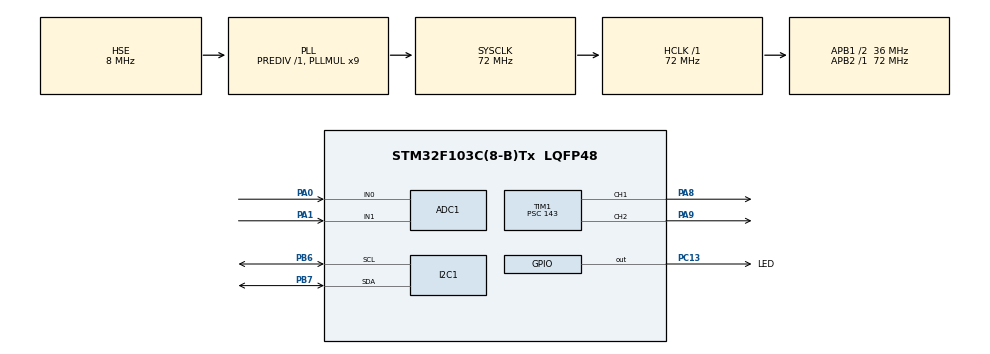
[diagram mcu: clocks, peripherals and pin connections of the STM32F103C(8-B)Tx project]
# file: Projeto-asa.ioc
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ADC1.Channel-0\#ChannelRegularConversion=ADC_CHANNEL_0
ADC1.Channel-1\#ChannelRegularConversion=ADC_CHANNEL_1
ADC1.ContinuousConvMode=DISABLE
ADC1.ExternalTrigConv=ADC_EXTERNALTRIGCONV_T3_TRGO
ADC1.NbrOfConversion=2
ADC1.NbrOfConversionFlag=1
ADC1.Rank-0\#ChannelRegularConversion=1
ADC1.Rank-1\#ChannelRegularConversion=2
ADC1.SamplingTime-0\#ChannelRegularConversion=ADC_SAMPLETIME_28CYCLES_5
ADC1.SamplingTime-1\#ChannelRegularConversion=ADC_SAMPLETIME_28CYCLES_5
ADC1.master=1
Dma.ADC1.0.Direction=DMA_PERIPH_TO_MEMORY
Dma.ADC1.0.Instance=DMA1_Channel1
Dma.ADC1.0.MemDataAlignment=DMA_MDATAALIGN_WORD
Dma.ADC1.0.MemInc=DMA_MINC_ENABLE
Dma.ADC1.0.Mode=DMA_CIRCULAR
Dma.ADC1.0.PeriphDataAlignment=DMA_PDATAALIGN_WORD
Dma.ADC1.0.PeriphInc=DMA_PINC_DISABLE
Dma.ADC1.0.Priority=DMA_PRIORITY_HIGH
Dma.Request0=ADC1
I2C1.I2C_Mode=I2C_Fast
Mcu.Family=STM32F1
Mcu.Name=STM32F103C(8-B)Tx
Mcu.Package=LQFP48
NVIC.ADC1_2_IRQn=true\:0\:0\:false\:false\:true\:true\:true
NVIC.DMA1_Channel1_IRQn=true\:0\:0\:false\:false\:true\:false\:true
NVIC.I2C1_ER_IRQn=true\:0\:0\:false\:false\:true\:true\:true
NVIC.I2C1_EV_IRQn=true\:0\:0\:false\:false\:true\:true\:true
NVIC.PriorityGroup=NVIC_PRIORITYGROUP_4
NVIC.TIM1_BRK_IRQn=true\:0\:0\:false\:false\:true\:true\:true
NVIC.TIM1_CC_IRQn=true\:0\:0\:false\:false\:true\:true\:true
NVIC.TIM1_TRG_COM_IRQn=true\:0\:0\:false\:false\:true\:true\:true
NVIC.TIM1_UP_IRQn=true\:0\:0\:false\:false\:true\:true\:true
PA0-WKUP.Signal=ADCx_IN0
PA1.Signal=ADCx_IN1
PA13.Mode=Serial_Wire
PA13.Signal=SYS_JTMS-SWDIO
PA14.Mode=Serial_Wire
PA14.Signal=SYS_JTCK-SWCLK
PA8.Signal=S_TIM1_CH1
PA9.Signal=S_TIM1_CH2
PB6.Mode=I2C
PB6.Signal=I2C1_SCL
PB7.Mode=I2C
PB7.Signal=I2C1_SDA
PC13-TAMPER-RTC.GPIO_Label=LED
PC13-TAMPER-RTC.Signal=GPIO_Output
PD0-OSC_IN.Mode=HSE-External-Clock-Source
PD0-OSC_IN.Signal=RCC_OSC_IN
PD1-OSC_OUT.Mode=HSE-External-Clock-Source
PD1-OSC_OUT.Signal=RCC_OSC_OUT
ProjectManager.HeapSize=0x200
ProjectManager.StackSize=0x400
ProjectManager.TargetToolchain=TrueSTUDIO
RCC.ADCPresc=RCC_ADCPCLK2_DIV8
RCC.AHBFreq_Value=72000000
RCC.APB1CLKDivider=RCC_HCLK_DIV2
RCC.APB1Freq_Value=36000000
RCC.APB1TimFreq_Value=72000000
RCC.APB2Freq_Value=72000000
RCC.APB2TimFreq_Value=72000000
RCC.HCLKFreq_Value=72000000
RCC.PLLMUL=RCC_PLL_MUL9
RCC.PLLSourceVirtual=RCC_PLLSOURCE_HSE
RCC.SYSCLKFreq_VALUE=72000000
RCC.SYSCLKSource=RCC_SYSCLKSOURCE_PLLCLK
RCC.USBFreq_Value=72000000
SH.ADCx_IN0.0=ADC1_IN0,IN0
SH.ADCx_IN1.0=ADC1_IN1,IN1
SH.S_TIM1_CH1.0=TIM1_CH1,PWM Generation1 CH1
SH.S_TIM1_CH2.0=TIM1_CH2,PWM Generation2 CH2
TIM1.Channel-PWM\ Generation1\ CH1=TIM_CHANNEL_1
TIM1.Channel-PWM\ Generation2\ CH2=TIM_CHANNEL_2
TIM1.Period=10000
TIM1.Prescaler=143
TIM1.Pulse-PWM\ Generation1\ CH1=5000
TIM1.Pulse-PWM\ Generation2\ CH2=4999
TIM3.Period=1439
TIM3.Prescaler=999
TIM3.TIM_MasterOutputTrigger=TIM_TRGO_UPDATE
VP_TIM3_VS_ClockSourceINT.Mode=Internal
board=custom

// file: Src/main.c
/* USER CODE BEGIN Header */
/**
  ******************************************************************************
  * @file           : main.c
  * @brief          : Main program body
  ******************************************************************************
  * @attention
  *
  * <h2><center>&copy; Copyright (c) 2019 STMicroelectronics.
  * All rights reserved.</center></h2>
  *
  * This software component is licensed by ST under BSD 3-Clause license,
  * the "License"; You may not use this file except in compliance with the
  * License. You may obtain a copy of the License at:
  *                        opensource.org/licenses/BSD-3-Clause
  *
  ******************************************************************************
  */
/* USER CODE END Header */

#include "main.h"

ADC_HandleTypeDef hadc1;
DMA_HandleTypeDef hdma_adc1;

I2C_HandleTypeDef hi2c1;

TIM_HandleTypeDef htim1;
TIM_HandleTypeDef htim3;

/* USER CODE BEGIN PV */
uint8_t rawMpu[6];
uint32_t rawAdc[2];
uint32_t servoPosition;
/* USER CODE END PV */

void SystemClock_Config(void);
static void MX_GPIO_Init(void);
static void MX_DMA_Init(void);
static void MX_ADC1_Init(void);
static void MX_I2C1_Init(void);
static void MX_TIM1_Init(void);
static void MX_TIM3_Init(void);

int main(void)
{
  /* USER CODE BEGIN 1 */
    uint8_t mpuConfig;
  /* USER CODE END 1 */

  /* MCU Configuration--------------------------------------------------------*/

  /* Reset of all peripherals, Initializes the Flash interface and the Systick. */
  HAL_Init();

  /* Configure the system clock */
  SystemClock_Config();

  /* Initialize all configured peripherals */
  MX_GPIO_Init();
  MX_DMA_Init();
  MX_ADC1_Init();
  MX_I2C1_Init();
  MX_TIM1_Init();
  MX_TIM3_Init();
  /* USER CODE BEGIN 2 */
 // mpuConfig = 0b00000000;
 // HAL_I2C_Mem_Write(&hi2c1, 0x68, 0x6B, I2C_MEMADD_SIZE_8BIT, &mpuConfig, 1, 100); //

  HAL_TIM_PWM_Start(&htim1, TIM_CHANNEL_1);
  HAL_TIM_PWM_Start(&htim1, TIM_CHANNEL_2);
  HAL_TIM_Base_Start_IT(&htim3);
  HAL_ADCEx_Calibration_Start(&hadc1);
  HAL_ADC_Start_DMA(&hadc1, (uint32_t*)rawAdc, 2);

  /* USER CODE END 2 */

  /* Infinite loop */
  while (1)
  {

    /* USER CODE BEGIN 3 */
	  HAL_Delay(100);
  }
  /* USER CODE END 3 */
}

void SystemClock_Config(void)
{
  RCC_OscInitTypeDef RCC_OscInitStruct = {0};
  RCC_ClkInitTypeDef RCC_ClkInitStruct = {0};
  RCC_PeriphCLKInitTypeDef PeriphClkInit = {0};

  /** Initializes the CPU, AHB and APB busses clocks
  */
  RCC_OscInitStruct.OscillatorType = RCC_OSCILLATORTYPE_HSE;
  RCC_OscInitStruct.HSEState = RCC_HSE_BYPASS;
  RCC_OscInitStruct.HSEPredivValue = RCC_HSE_PREDIV_DIV1;
  RCC_OscInitStruct.HSIState = RCC_HSI_ON;
  RCC_OscInitStruct.PLL.PLLState = RCC_PLL_ON;
  RCC_OscInitStruct.PLL.PLLSource = RCC_PLLSOURCE_HSE;
  RCC_OscInitStruct.PLL.PLLMUL = RCC_PLL_MUL9;
  if (HAL_RCC_OscConfig(&RCC_OscInitStruct) != HAL_OK)
  {
    Error_Handler();
  }
  /** Initializes the CPU, AHB and APB busses clocks
  */
  RCC_ClkInitStruct.ClockType = RCC_CLOCKTYPE_HCLK|RCC_CLOCKTYPE_SYSCLK
                              |RCC_CLOCKTYPE_PCLK1|RCC_CLOCKTYPE_PCLK2;
  RCC_ClkInitStruct.SYSCLKSource = RCC_SYSCLKSOURCE_PLLCLK;
  RCC_ClkInitStruct.AHBCLKDivider = RCC_SYSCLK_DIV1;
  RCC_ClkInitStruct.APB1CLKDivider = RCC_HCLK_DIV2;
  RCC_ClkInitStruct.APB2CLKDivider = RCC_HCLK_DIV1;

  if (HAL_RCC_ClockConfig(&RCC_ClkInitStruct, FLASH_LATENCY_2) != HAL_OK)
  {
    Error_Handler();
  }
  PeriphClkInit.PeriphClockSelection = RCC_PERIPHCLK_ADC;
  PeriphClkInit.AdcClockSelection = RCC_ADCPCLK2_DIV8;
  if (HAL_RCCEx_PeriphCLKConfig(&PeriphClkInit) != HAL_OK)
  {
    Error_Handler();
  }
}

static void MX_ADC1_Init(void)
{

  ADC_ChannelConfTypeDef sConfig = {0};

  /** Common config
  */
  hadc1.Instance = ADC1;
  hadc1.Init.ScanConvMode = ADC_SCAN_ENABLE;
  hadc1.Init.ContinuousConvMode = DISABLE;
  hadc1.Init.DiscontinuousConvMode = DISABLE;
  hadc1.Init.ExternalTrigConv = ADC_EXTERNALTRIGCONV_T3_TRGO;
  hadc1.Init.DataAlign = ADC_DATAALIGN_RIGHT;
  hadc1.Init.NbrOfConversion = 2;
  if (HAL_ADC_Init(&hadc1) != HAL_OK)
  {
    Error_Handler();
  }
  /** Configure Regular Channel
  */
  sConfig.Channel = ADC_CHANNEL_0;
  sConfig.Rank = ADC_REGULAR_RANK_1;
  sConfig.SamplingTime = ADC_SAMPLETIME_28CYCLES_5;
  if (HAL_ADC_ConfigChannel(&hadc1, &sConfig) != HAL_OK)
  {
    Error_Handler();
  }
  /** Configure Regular Channel
  */
  sConfig.Channel = ADC_CHANNEL_1;
  sConfig.Rank = ADC_REGULAR_RANK_2;
  if (HAL_ADC_ConfigChannel(&hadc1, &sConfig) != HAL_OK)
  {
    Error_Handler();
  }

}

static void MX_I2C1_Init(void)
{

  hi2c1.Instance = I2C1;
  hi2c1.Init.ClockSpeed = 400000;
  hi2c1.Init.DutyCycle = I2C_DUTYCYCLE_2;
  hi2c1.Init.OwnAddress1 = 0;
  hi2c1.Init.AddressingMode = I2C_ADDRESSINGMODE_7BIT;
  hi2c1.Init.DualAddressMode = I2C_DUALADDRESS_DISABLE;
  hi2c1.Init.OwnAddress2 = 0;
  hi2c1.Init.GeneralCallMode = I2C_GENERALCALL_DISABLE;
  hi2c1.Init.NoStretchMode = I2C_NOSTRETCH_DISABLE;
  if (HAL_I2C_Init(&hi2c1) != HAL_OK)
  {
    Error_Handler();
  }

}

static void MX_TIM1_Init(void)
{

  TIM_MasterConfigTypeDef sMasterConfig = {0};
  TIM_OC_InitTypeDef sConfigOC = {0};
  TIM_BreakDeadTimeConfigTypeDef sBreakDeadTimeConfig = {0};

  htim1.Instance = TIM1;
  htim1.Init.Prescaler = 143;
  htim1.Init.CounterMode = TIM_COUNTERMODE_UP;
  htim1.Init.Period = 10000;
  htim1.Init.ClockDivision = TIM_CLOCKDIVISION_DIV1;
  htim1.Init.RepetitionCounter = 0;
  htim1.Init.AutoReloadPreload = TIM_AUTORELOAD_PRELOAD_DISABLE;
  if (HAL_TIM_PWM_Init(&htim1) != HAL_OK)
  {
    Error_Handler();
  }
  sMasterConfig.MasterOutputTrigger = TIM_TRGO_RESET;
  sMasterConfig.MasterSlaveMode = TIM_MASTERSLAVEMODE_DISABLE;
  if (HAL_TIMEx_MasterConfigSynchronization(&htim1, &sMasterConfig) != HAL_OK)
  {
    Error_Handler();
  }
  sConfigOC.OCMode = TIM_OCMODE_PWM1;
  sConfigOC.Pulse = 5000;
  sConfigOC.OCPolarity = TIM_OCPOLARITY_HIGH;
  sConfigOC.OCNPolarity = TIM_OCNPOLARITY_HIGH;
  sConfigOC.OCFastMode = TIM_OCFAST_DISABLE;
  sConfigOC.OCIdleState = TIM_OCIDLESTATE_RESET;
  sConfigOC.OCNIdleState = TIM_OCNIDLESTATE_RESET;
  if (HAL_TIM_PWM_ConfigChannel(&htim1, &sConfigOC, TIM_CHANNEL_1) != HAL_OK)
  {
    Error_Handler();
  }
  sConfigOC.Pulse = 4999;
  if (HAL_TIM_PWM_ConfigChannel(&htim1, &sConfigOC, TIM_CHANNEL_2) != HAL_OK)
  {
    Error_Handler();
  }
  sBreakDeadTimeConfig.OffStateRunMode = TIM_OSSR_DISABLE;
  sBreakDeadTimeConfig.OffStateIDLEMode = TIM_OSSI_DISABLE;
  sBreakDeadTimeConfig.LockLevel = TIM_LOCKLEVEL_OFF;
  sBreakDeadTimeConfig.DeadTime = 0;
  sBreakDeadTimeConfig.BreakState = TIM_BREAK_DISABLE;
  sBreakDeadTimeConfig.BreakPolarity = TIM_BREAKPOLARITY_HIGH;
  sBreakDeadTimeConfig.AutomaticOutput = TIM_AUTOMATICOUTPUT_DISABLE;
  if (HAL_TIMEx_ConfigBreakDeadTime(&htim1, &sBreakDeadTimeConfig) != HAL_OK)
  {
    Error_Handler();
  }
  HAL_TIM_MspPostInit(&htim1);

}

static void MX_TIM3_Init(void)
{

  TIM_ClockConfigTypeDef sClockSourceConfig = {0};
  TIM_MasterConfigTypeDef sMasterConfig = {0};

  htim3.Instance = TIM3;
  htim3.Init.Prescaler = 999;
  htim3.Init.CounterMode = TIM_COUNTERMODE_UP;
  htim3.Init.Period = 1439;
  htim3.Init.ClockDivision = TIM_CLOCKDIVISION_DIV1;
  htim3.Init.AutoReloadPreload = TIM_AUTORELOAD_PRELOAD_DISABLE;
  if (HAL_TIM_Base_Init(&htim3) != HAL_OK)
  {
    Error_Handler();
  }
  sClockSourceConfig.ClockSource = TIM_CLOCKSOURCE_INTERNAL;
  if (HAL_TIM_ConfigClockSource(&htim3, &sClockSourceConfig) != HAL_OK)
  {
    Error_Handler();
  }
  sMasterConfig.MasterOutputTrigger = TIM_TRGO_UPDATE;
  sMasterConfig.MasterSlaveMode = TIM_MASTERSLAVEMODE_DISABLE;
  if (HAL_TIMEx_MasterConfigSynchronization(&htim3, &sMasterConfig) != HAL_OK)
  {
    Error_Handler();
  }

}

static void MX_DMA_Init(void)
{

  /* DMA controller clock enable */
  __HAL_RCC_DMA1_CLK_ENABLE();

  /* DMA interrupt init */
  /* DMA1_Channel1_IRQn interrupt configuration */
  HAL_NVIC_SetPriority(DMA1_Channel1_IRQn, 0, 0);
  HAL_NVIC_EnableIRQ(DMA1_Channel1_IRQn);

}

static void MX_GPIO_Init(void)
{
  GPIO_InitTypeDef GPIO_InitStruct = {0};

  /* GPIO Ports Clock Enable */
  __HAL_RCC_GPIOC_CLK_ENABLE();
  __HAL_RCC_GPIOD_CLK_ENABLE();
  __HAL_RCC_GPIOA_CLK_ENABLE();
  __HAL_RCC_GPIOB_CLK_ENABLE();

  /*Configure GPIO pin Output Level */
  HAL_GPIO_WritePin(LED_GPIO_Port, LED_Pin, GPIO_PIN_RESET);

  /*Configure GPIO pin : LED_Pin */
  GPIO_InitStruct.Pin = LED_Pin;
  GPIO_InitStruct.Mode = GPIO_MODE_OUTPUT_PP;
  GPIO_InitStruct.Pull = GPIO_NOPULL;
  GPIO_InitStruct.Speed = GPIO_SPEED_FREQ_LOW;
  HAL_GPIO_Init(LED_GPIO_Port, &GPIO_InitStruct);

}

/* USER CODE BEGIN 4 */

void HAL_ADC_ConvCpltCallback(ADC_HandleTypeDef *hadc)
{
	/* Prevent unused argument(s) compilation warning */
	UNUSED(hadc);
	/* NOTE : This function should not be modified. When the callback is needed,
			function HAL_ADC_ConvCpltCallback must be implemented in the user file.
	 */
  //  HAL_I2C_Mem_Read_IT(&hi2c1, 0x68, 0x3B, I2C_MEMADD_SIZE_8BIT, rawMpu, 6);
    HAL_GPIO_TogglePin(GPIOC,LED_Pin);
}
/*
void HAL_I2C_MemRxCpltCallback(I2C_HandleTypeDef *hi2c)
{
    HAL_GPIO_TogglePin(GPIOB, GPIO_PIN_13);
    uint32_t xAcc = (rawMpu[0] << 8) | (0x00F0 & rawMpu[1]);
    uint32_t yAcc = (rawMpu[2] << 8) | (0x00F0 & rawMpu[3]);
    uint32_t zAcc = (rawMpu[4] << 8) | (0x00F0 & rawMpu[5]);

    uint32_t servoPosition = 50 + 0.005* xAcc;
    htim1.Instance->CCR1 = servoPosition;
}
*/
/* USER CODE END 4 */

void Error_Handler(void)
{
}

/************************ (C) COPYRIGHT STMicroelectronics *****END OF FILE****/
